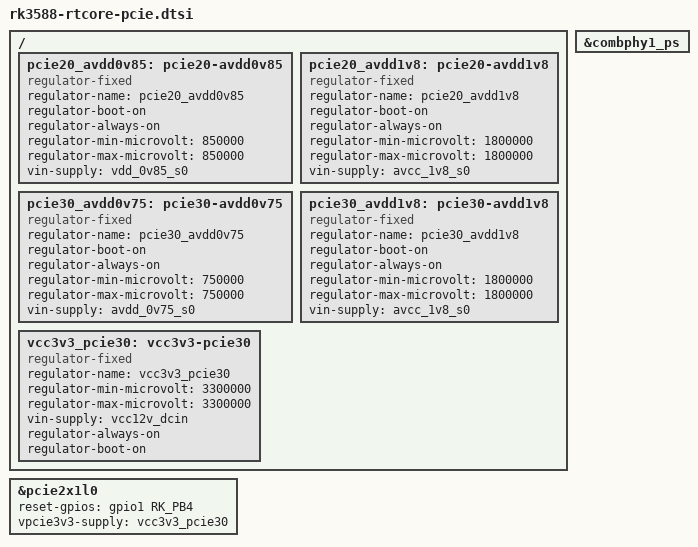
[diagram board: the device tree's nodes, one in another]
/ {
	pcie20_avdd0v85: pcie20-avdd0v85 {
		compatible = "regulator-fixed";
		regulator-name = "pcie20_avdd0v85";
		regulator-boot-on;
		regulator-always-on;
		regulator-min-microvolt = <850000>;
		regulator-max-microvolt = <850000>;
		vin-supply = <&vdd_0v85_s0>;
	};

	pcie20_avdd1v8: pcie20-avdd1v8 {
		compatible = "regulator-fixed";
		regulator-name = "pcie20_avdd1v8";
		regulator-boot-on;
		regulator-always-on;
		regulator-min-microvolt = <1800000>;
		regulator-max-microvolt = <1800000>;
		vin-supply = <&avcc_1v8_s0>;
	};

	pcie30_avdd0v75: pcie30-avdd0v75 {
		compatible = "regulator-fixed";
		regulator-name = "pcie30_avdd0v75";
		regulator-boot-on;
		regulator-always-on;
		regulator-min-microvolt = <750000>;
		regulator-max-microvolt = <750000>;
		vin-supply = <&avdd_0v75_s0>;
	};

	pcie30_avdd1v8: pcie30-avdd1v8 {
		compatible = "regulator-fixed";
		regulator-name = "pcie30_avdd1v8";
		regulator-boot-on;
		regulator-always-on;
		regulator-min-microvolt = <1800000>;
		regulator-max-microvolt = <1800000>;
		vin-supply = <&avcc_1v8_s0>;
	};

	vcc3v3_pcie30: vcc3v3-pcie30 {
		compatible = "regulator-fixed";
		regulator-name = "vcc3v3_pcie30";
		regulator-min-microvolt = <3300000>;
		regulator-max-microvolt = <3300000>;
		vin-supply = <&vcc12v_dcin>;
		regulator-always-on;
		regulator-boot-on;
	};
};
#if 1
&combphy1_ps {
    status = "okay";
};

&pcie2x1l0 {
	reset-gpios = <&gpio1 RK_PB4 GPIO_ACTIVE_HIGH>;
	vpcie3v3-supply = <&vcc3v3_pcie30>;
	status = "okay";
};
#endif

#if 0
&pcie30phy {
	rockchip,pcie30-phymode = <PHY_MODE_PCIE_NABINB>; /* P1:PCIe3x1*2 + P0:PCIe3x2 */
	status = "okay";
};

&pcie3x2 {
	num-lanes = <1>;
	reset-gpios = <&gpio4 RK_PB6 GPIO_ACTIVE_HIGH>;
	vpcie3v3-supply = <&vcc3v3_pcie30>;
	status = "okay";
};
#endif
